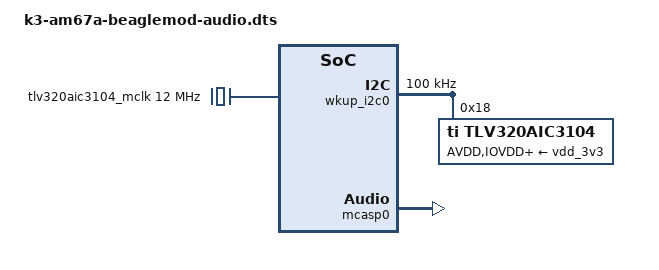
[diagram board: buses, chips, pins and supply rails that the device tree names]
// SPDX-License-Identifier: GPL-2.0
/*
 * Copyright (C) 2022 Texas Instruments Incorporated - https://www.ti.com/
 */

/dts-v1/;
/plugin/;

// #include <dt-bindings/leds/common.h>
// #include <dt-bindings/net/ti-dp83867.h>
// #include "k3-j722s.dtsi"

#include "k3-pinctrl.h"

&{/} {
	tlv320aic3104_mclk: tlv320aic3104_mclk {
		#clock-cells = <0>;
		compatible = "fixed-clock";
		clock-frequency = <12000000>;
	};

	sound {
		compatible = "simple-audio-card";
		simple-audio-card,format = "i2s";
		simple-audio-card,name = "beaglemod voice";
		simple-audio-card,bitclock-master = <&dailink0_master>;
		simple-audio-card,frame-master = <&dailink0_master>;
		status = "okay";

		simple-audio-card,widgets =
			"Headphone", "Headphone Jack",
			"Line", "Line In";
		simple-audio-card,routing =
			"Headphone Jack",       "HPLOUT",
			"Headphone Jack",       "HPROUT",
			"LINE1L",               "Line In",
			"LINE1R",               "Line In";
		dailink0_master: simple-audio-card,cpu {
			sound-dai = <&mcasp0>;
			system-clock-direction-out;
		};
		simple-audio-card,codec {
			sound-dai = <&tlv320aic3104>;
			clocks = <&tlv320aic3104_mclk>;
		};
	};
};

&main_pmx0 {
	mcasp_codec_pins_default: mcasp0-codec-pins-default {
		pinctrl-single,pins = <
			J722S_MCU_IOPAD(0x01a4, PIN_INPUT, 0) /* (D25) MCASP0_ACLKX */
			J722S_MCU_IOPAD(0x01a8, PIN_INPUT, 0) /* (C26) MCASP0_AFSX */
			J722S_MCU_IOPAD(0x01a0, PIN_INPUT, 0) /* (F24) MCASP0_AXR0 */
			J722S_MCU_IOPAD(0x019c, PIN_OUTPUT, 0) /* (B25) MCASP0_AXR1 */
		>;
	};
};

&mcu_pmx0 {
    wkup_i2c0_pins_default: mywkup-i2c0-default-pins {
		pinctrl-single,pins = <
			J722S_MCU_IOPAD(0x004c, PIN_INPUT, 0) /* (B9) WKUP_I2C0_SCL */
			J722S_MCU_IOPAD(0x0050, PIN_INPUT, 0) /* (D11) WKUP_I2C1_SDA */
		>;
		bootph-all;
	};
};

&wkup_i2c0 {
	pinctrl-names = "default";
	pinctrl-0 = <&wkup_i2c0_pins_default>;
	clock-frequency = <100000>;
	bootph-all;
	#address-cells = <1>;
	#size-cells = <0>;
	status = "okay";

	tlv320aic3104: tlv320aic3104@18 {
		#sound-dai-cells = <0>;
		compatible = "ti,tlv320aic3104";
		reg = <0x18>;
		status = "okay";

		ai3x-micbias-vg = <2>; // set MICBIAS to 2.5v
		AVDD-supply = <&vdd_3v3>;
		IOVDD-supply = <&vdd_3v3>;
		DRVDD-supply = <&vdd_3v3>;
		DVDD-supply = <&vdd_3v3>;
	};
};

&mcasp0 {
	status = "okay";
	pinctrl-names = "default";
	pinctrl-0 = <&mcasp_codec_pins_default>;

	#sound-dai-cells = <0>;

	op-mode = <0>;          /* MCASP_IIS_MODE */
	tdm-slots = <2>;

	serial-dir = <  /* 0: INACTIVE, 1: TX, 2: RX */
	       2 1 0 0
	       0 0 0 0
	       0 0 0 0
	       0 0 0 0
	>;
	tx-num-evt = <32>;
	rx-num-evt = <32>;
};
